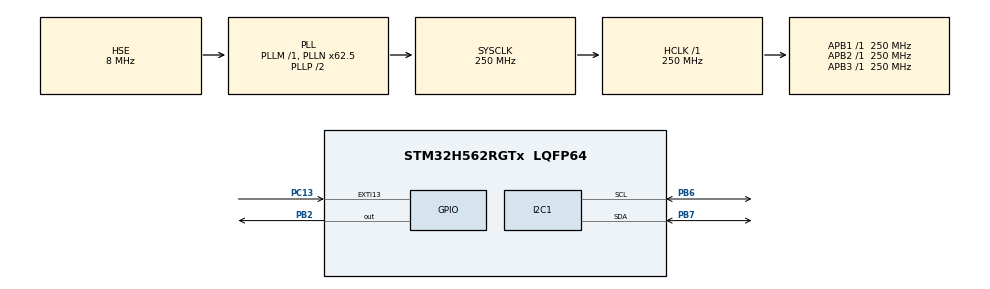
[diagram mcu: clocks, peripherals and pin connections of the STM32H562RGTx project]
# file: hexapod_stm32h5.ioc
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CORTEX_M33_NS.userName=CORTEX_M33
I2C1.Speed=100
I2C1.Timing=0x60808CD3
Mcu.Family=STM32H5
Mcu.Name=STM32H562RGTx
Mcu.Package=LQFP64
NVIC.EXTI13_IRQn=true\:0\:0\:false\:false\:true\:true\:true\:true
NVIC.I2C1_EV_IRQn=true\:0\:0\:false\:false\:true\:true\:true\:true
NVIC.PriorityGroup=NVIC_PRIORITYGROUP_4
PB2.GPIO_PuPd=GPIO_PULLUP
PB2.Signal=GPIO_Output
PB6.GPIO_Mode=GPIO_MODE_AF_OD
PB6.GPIO_Pu=GPIO_PULLUP
PB6.GPIO_Speed=GPIO_SPEED_FREQ_MEDIUM
PB6.Mode=I2C
PB6.Signal=I2C1_SCL
PB7.GPIO_Pu=GPIO_PULLUP
PB7.GPIO_Speed=GPIO_SPEED_FREQ_MEDIUM
PB7.Mode=I2C
PB7.Signal=I2C1_SDA
PC13.GPIO_PuPd=GPIO_PULLUP
PC13.Signal=GPXTI13
PH0-OSC_IN(PH0).Mode=HSE-External-Oscillator
PH0-OSC_IN(PH0).Signal=RCC_OSC_IN
PH1-OSC_OUT(PH1).Mode=HSE-External-Oscillator
PH1-OSC_OUT(PH1).Signal=RCC_OSC_OUT
ProjectManager.HeapSize=0x200
ProjectManager.StackSize=0x400
ProjectManager.TargetToolchain=STM32CubeIDE
RCC.ADCFreq_Value=250000000
RCC.AHBFreq_Value=250000000
RCC.APB1Freq_Value=250000000
RCC.APB1TimFreq_Value=250000000
RCC.APB2Freq_Value=250000000
RCC.APB2TimFreq_Value=250000000
RCC.APB3Freq_Value=250000000
RCC.CSI_VALUE=4000000
RCC.CortexFreq_Value=250000000
RCC.EPOD_VALUE=8000000
RCC.HCLKFreq_Value=250000000
RCC.HSE_VALUE=8000000
RCC.HSI48_VALUE=48000000
RCC.HSI_VALUE=64000000
RCC.LSE_VALUE=32768
RCC.LSIRC_VALUE=32000
RCC.PLL2FRACN=0
RCC.PLL3FRACN=0
RCC.PLLFRACN=4096
RCC.PLLN=62
RCC.PLLSourceVirtual=RCC_PLL1_SOURCE_HSE
RCC.SYSCLKFreq_VALUE=250000000
RCC.SYSCLKSource=RCC_SYSCLKSOURCE_PLLCLK
RCC.USBFreq_Value=48000000
RCC.VCOOutputFreq_Value=500000000
VP_BOOTPATH_VS_BOOTPATH.Mode=BP_Activate
VP_MEMORYMAP_VS_MEMORYMAP.Mode=CurAppReg
VP_PWR_VS_DBSignals.Mode=DisableDeadBatterySignals
VP_PWR_VS_LPOM.Mode=PowerOptimisation
VP_PWR_VS_SECSignals.Mode=Security/Privilege
board=custom

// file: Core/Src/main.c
/* USER CODE BEGIN Header */
/**
  ******************************************************************************
  * @file           : main.c
  * @brief          : Main program body
  ******************************************************************************
  * @attention
  *
  * Copyright (c) 2024 STMicroelectronics.
  * All rights reserved.
  *
  * This software is licensed under terms that can be found in the LICENSE file
  * in the root directory of this software component.
  * If no LICENSE file comes with this software, it is provided AS-IS.
  *
  ******************************************************************************
  */
/* USER CODE END Header */
#include "main.h"

I2C_HandleTypeDef hi2c1;

/* USER CODE BEGIN PV */
uint16_t loop_counter = 0;

/* USER CODE END PV */

void SystemClock_Config(void);
static void MX_GPIO_Init(void);
static void MX_MEMORYMAP_Init(void);
static void MX_I2C1_Init(void);

int main(void)
{

  /* MCU Configuration--------------------------------------------------------*/

  /* Reset of all peripherals, Initializes the Flash interface and the Systick. */
  HAL_Init();

  /* Configure the system clock */
  SystemClock_Config();

  /* Initialize all configured peripherals */
  MX_GPIO_Init();
  MX_MEMORYMAP_Init();
  MX_I2C1_Init();

  /* Infinite loop */
  while (1)
  {

    /* USER CODE BEGIN 3 */
	  loop_counter++;
	  if (loop_counter >=1000) loop_counter = 0 ;
  }
  /* USER CODE END 3 */
}

void SystemClock_Config(void)
{
  RCC_OscInitTypeDef RCC_OscInitStruct = {0};
  RCC_ClkInitTypeDef RCC_ClkInitStruct = {0};

  /** Configure the main internal regulator output voltage
  */
  __HAL_PWR_VOLTAGESCALING_CONFIG(PWR_REGULATOR_VOLTAGE_SCALE0);

  while(!__HAL_PWR_GET_FLAG(PWR_FLAG_VOSRDY)) {}

  /** Initializes the RCC Oscillators according to the specified parameters
  * in the RCC_OscInitTypeDef structure.
  */
  RCC_OscInitStruct.OscillatorType = RCC_OSCILLATORTYPE_HSE;
  RCC_OscInitStruct.HSEState = RCC_HSE_ON;
  RCC_OscInitStruct.PLL.PLLState = RCC_PLL_ON;
  RCC_OscInitStruct.PLL.PLLSource = RCC_PLL1_SOURCE_HSE;
  RCC_OscInitStruct.PLL.PLLM = 1;
  RCC_OscInitStruct.PLL.PLLN = 62;
  RCC_OscInitStruct.PLL.PLLP = 2;
  RCC_OscInitStruct.PLL.PLLQ = 2;
  RCC_OscInitStruct.PLL.PLLR = 2;
  RCC_OscInitStruct.PLL.PLLRGE = RCC_PLL1_VCIRANGE_3;
  RCC_OscInitStruct.PLL.PLLVCOSEL = RCC_PLL1_VCORANGE_WIDE;
  RCC_OscInitStruct.PLL.PLLFRACN = 4096;
  if (HAL_RCC_OscConfig(&RCC_OscInitStruct) != HAL_OK)
  {
    Error_Handler();
  }

  /** Initializes the CPU, AHB and APB buses clocks
  */
  RCC_ClkInitStruct.ClockType = RCC_CLOCKTYPE_HCLK|RCC_CLOCKTYPE_SYSCLK
                              |RCC_CLOCKTYPE_PCLK1|RCC_CLOCKTYPE_PCLK2
                              |RCC_CLOCKTYPE_PCLK3;
  RCC_ClkInitStruct.SYSCLKSource = RCC_SYSCLKSOURCE_PLLCLK;
  RCC_ClkInitStruct.AHBCLKDivider = RCC_SYSCLK_DIV1;
  RCC_ClkInitStruct.APB1CLKDivider = RCC_HCLK_DIV1;
  RCC_ClkInitStruct.APB2CLKDivider = RCC_HCLK_DIV1;
  RCC_ClkInitStruct.APB3CLKDivider = RCC_HCLK_DIV1;

  if (HAL_RCC_ClockConfig(&RCC_ClkInitStruct, FLASH_LATENCY_5) != HAL_OK)
  {
    Error_Handler();
  }
}

static void MX_I2C1_Init(void)
{

  hi2c1.Instance = I2C1;
  hi2c1.Init.Timing = 0x60808CD3;
  hi2c1.Init.OwnAddress1 = 0;
  hi2c1.Init.AddressingMode = I2C_ADDRESSINGMODE_7BIT;
  hi2c1.Init.DualAddressMode = I2C_DUALADDRESS_DISABLE;
  hi2c1.Init.OwnAddress2 = 0;
  hi2c1.Init.OwnAddress2Masks = I2C_OA2_NOMASK;
  hi2c1.Init.GeneralCallMode = I2C_GENERALCALL_DISABLE;
  hi2c1.Init.NoStretchMode = I2C_NOSTRETCH_DISABLE;
  if (HAL_I2C_Init(&hi2c1) != HAL_OK)
  {
    Error_Handler();
  }

  /** Configure Analogue filter
  */
  if (HAL_I2CEx_ConfigAnalogFilter(&hi2c1, I2C_ANALOGFILTER_ENABLE) != HAL_OK)
  {
    Error_Handler();
  }

  /** Configure Digital filter
  */
  if (HAL_I2CEx_ConfigDigitalFilter(&hi2c1, 0) != HAL_OK)
  {
    Error_Handler();
  }

}

static void MX_MEMORYMAP_Init(void)
{

}

static void MX_GPIO_Init(void)
{
  GPIO_InitTypeDef GPIO_InitStruct = {0};

  /* GPIO Ports Clock Enable */
  __HAL_RCC_GPIOC_CLK_ENABLE();
  __HAL_RCC_GPIOH_CLK_ENABLE();
  __HAL_RCC_GPIOB_CLK_ENABLE();

  /*Configure GPIO pin Output Level */
  HAL_GPIO_WritePin(GPIOB, GPIO_PIN_2, GPIO_PIN_RESET);

  /*Configure GPIO pin : PC13 */
  GPIO_InitStruct.Pin = GPIO_PIN_13;
  GPIO_InitStruct.Mode = GPIO_MODE_IT_RISING;
  GPIO_InitStruct.Pull = GPIO_PULLUP;
  HAL_GPIO_Init(GPIOC, &GPIO_InitStruct);

  /*Configure GPIO pin : PB2 */
  GPIO_InitStruct.Pin = GPIO_PIN_2;
  GPIO_InitStruct.Mode = GPIO_MODE_OUTPUT_PP;
  GPIO_InitStruct.Pull = GPIO_PULLUP;
  GPIO_InitStruct.Speed = GPIO_SPEED_FREQ_LOW;
  HAL_GPIO_Init(GPIOB, &GPIO_InitStruct);

  /* EXTI interrupt init*/
  HAL_NVIC_SetPriority(EXTI13_IRQn, 0, 0);
  HAL_NVIC_EnableIRQ(EXTI13_IRQn);

}

void Error_Handler(void)
{
  __disable_irq();
  while (1)
  {
  }
}
